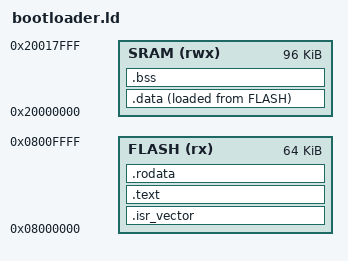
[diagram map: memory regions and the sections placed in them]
/*
 * Linker script — Bootloader
 * STM32G474RE  (Cortex-M4, 512KB flash, single-bank 2KB pages)
 *
 * Occupies the first 64KB of flash.  The application lives above us
 * starting at 0x0801 0000.
 */

MEMORY
{
    FLASH (rx)  : ORIGIN = 0x08000000, LENGTH = 64K
    SRAM  (rwx) : ORIGIN = 0x20000000, LENGTH = 96K   /* SRAM1 + SRAM2 */
}

_estack = ORIGIN(SRAM) + LENGTH(SRAM);

ENTRY(Reset_Handler)

SECTIONS
{
    .isr_vector :
    {
        . = ALIGN(4);
        KEEP(*(.isr_vector))
        . = ALIGN(4);
    } > FLASH

    .text :
    {
        . = ALIGN(4);
        *(.text)
        *(.text*)
        *(.glue_7)
        *(.glue_7t)
        KEEP(*(.init))
        KEEP(*(.fini))
        . = ALIGN(4);
        _etext = .;
    } > FLASH

    .rodata :
    {
        . = ALIGN(4);
        *(.rodata)
        *(.rodata*)
        . = ALIGN(4);
    } > FLASH

    /* Initialised data — stored in flash, copied to SRAM by startup */
    _sidata = LOADADDR(.data);

    .data :
    {
        . = ALIGN(4);
        _sdata = .;
        *(.data)
        *(.data*)
        . = ALIGN(4);
        _edata = .;
    } > SRAM AT> FLASH

    .bss (NOLOAD) :
    {
        . = ALIGN(4);
        _sbss = .;
        *(.bss)
        *(.bss*)
        *(COMMON)
        . = ALIGN(4);
        _ebss = .;
    } > SRAM

    /DISCARD/ :
    {
        *(.comment)
        *(.eh_frame)
    }

    .ARM.attributes 0 : { *(.ARM.attributes) }
}
